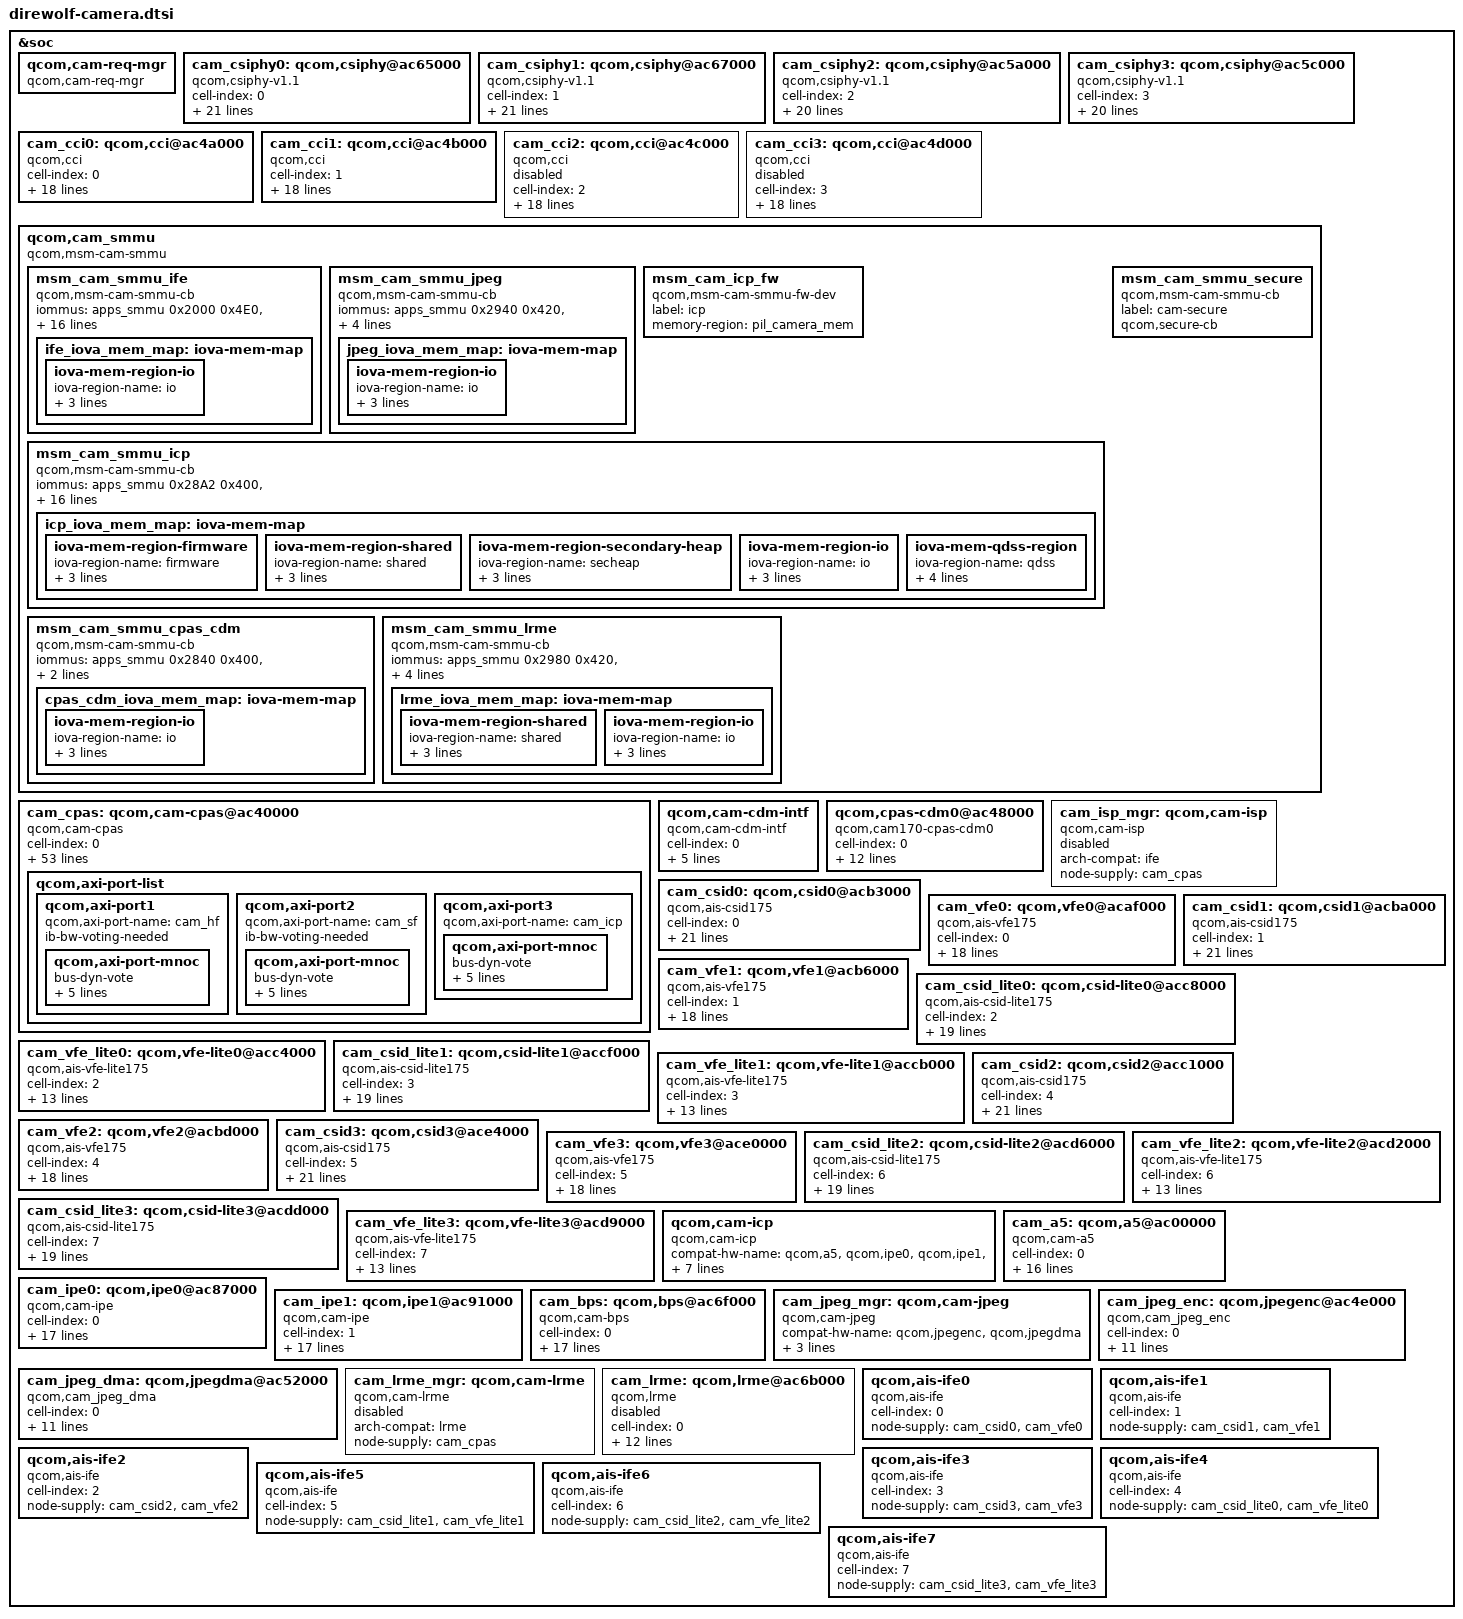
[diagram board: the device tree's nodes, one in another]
#include <dt-bindings/regulator/qcom,rpmh-regulator-levels.h>

&soc {
	qcom,cam-req-mgr {
		compatible = "qcom,cam-req-mgr";
		status = "ok";
	};

	cam_csiphy0: qcom,csiphy@ac65000 {
		cell-index = <0>;
		compatible = "qcom,csiphy-v1.1", "qcom,csiphy";
		reg = <0x0ac65000 0x2000>;
		reg-names = "csiphy";
		reg-cam-base = <0x65000>;
		interrupts = <GIC_SPI 477 IRQ_TYPE_EDGE_RISING>;
		interrupt-names = "csiphy";
		gdscr-supply = <&cam_cc_titan_top_gdsc>;
		csi-vdd-voltage = <1200000>;
		mipi-csi-vdd-supply = <&pm8540_a0_l11>;
		mipi-csi-vdd1p2-supply = <&pm8540_a0_l3>;
		regulator-names = "gdscr", "mipi-csi-vdd", "mipi-csi-vdd1p2";
		rgltr-cntrl-support;
		rgltr-min-voltage = <0 880000 1200000>;
		rgltr-max-voltage = <0 880000 1200000>;
		rgltr-load-current = <0 36000 21800>;
		clocks = <&camcc CAM_CC_CPHY_RX_CLK_SRC>,
			<&camcc CAM_CC_CSIPHY0_CLK>,
			<&camcc CAM_CC_CSI0PHYTIMER_CLK_SRC>,
			<&camcc CAM_CC_CSI0PHYTIMER_CLK>;
		clock-names = "cphy_rx_clk_src",
			"csiphy0_clk",
			"csi0phytimer_clk_src",
			"csi0phytimer_clk";
		src-clock-name = "csi0phytimer_clk_src";
		clock-cntl-level = "turbo";
		clock-rates =
			<400000000 0 300000000 0>;
		status = "ok";
		node-supply = <&cam_cpas>;
	};

	cam_csiphy1: qcom,csiphy@ac67000{
		cell-index = <1>;
		compatible = "qcom,csiphy-v1.1", "qcom,csiphy";
		reg = <0xac67000 0x2000>;
		reg-names = "csiphy";
		reg-cam-base = <0x67000>;
		interrupts = <GIC_SPI 478 IRQ_TYPE_EDGE_RISING>;
		interrupt-names = "csiphy";
		gdscr-supply = <&cam_cc_titan_top_gdsc>;
		csi-vdd-voltage = <1200000>;
		mipi-csi-vdd-supply = <&pm8540_a0_l11>;
		mipi-csi-vdd1p2-supply = <&pm8540_a0_l3>;
		regulator-names = "gdscr", "mipi-csi-vdd", "mipi-csi-vdd1p2";
		rgltr-cntrl-support;
		rgltr-min-voltage = <0 880000 1200000>;
		rgltr-max-voltage = <0 880000 1200000>;
		rgltr-load-current = <0 36000 21800>;
		clocks = <&camcc CAM_CC_CPHY_RX_CLK_SRC>,
			<&camcc CAM_CC_CSIPHY1_CLK>,
			<&camcc CAM_CC_CSI1PHYTIMER_CLK_SRC>,
			<&camcc CAM_CC_CSI1PHYTIMER_CLK>;
		clock-names = "cphy_rx_clk_src",
			"csiphy1_clk",
			"csi1phytimer_clk_src",
			"csi1phytimer_clk";
		src-clock-name = "csi1phytimer_clk_src";
		clock-cntl-level = "turbo";
		clock-rates =
			<400000000 0 300000000 0>;
		status = "ok";
		node-supply = <&cam_cpas>;
	};

	cam_csiphy2: qcom,csiphy@ac5a000 {
		cell-index = <2>;
		compatible = "qcom,csiphy-v1.1", "qcom,csiphy";
		reg = <0xac5a000 0x2000>;
		reg-names = "csiphy";
		reg-cam-base = <0x5a000>;
		interrupts = <GIC_SPI 479 IRQ_TYPE_EDGE_RISING>;
		interrupt-names = "csiphy";
		gdscr-supply = <&cam_cc_titan_top_gdsc>;
		csi-vdd-voltage = <1200000>;
		mipi-csi-vdd-supply = <&pm8540_g0_l8>;
		mipi-csi-vdd1p2-supply = <&pm8540_g0_l3>;
		regulator-names = "gdscr", "mipi-csi-vdd", "mipi-csi-vdd1p2";
		//rgltr-cntrl-support;
		rgltr-min-voltage = <0 880000 1200000>;
		rgltr-max-voltage = <0 880000 1200000>;
		rgltr-load-current = <0 36000 21800>;
		clocks = <&camcc CAM_CC_CPHY_RX_CLK_SRC>,
			<&camcc CAM_CC_CSIPHY2_CLK>,
			<&camcc CAM_CC_CSI2PHYTIMER_CLK_SRC>,
			<&camcc CAM_CC_CSI2PHYTIMER_CLK>;
		clock-names = "cphy_rx_clk_src",
			"csiphy2_clk",
			"csi2phytimer_clk_src",
			"csi2phytimer_clk";
		src-clock-name = "csi2phytimer_clk_src";
		clock-cntl-level = "turbo";
		clock-rates =
			<400000000 0 300000000 0>;
		status = "ok";
		node-supply = <&cam_cpas>;
	};

	cam_csiphy3: qcom,csiphy@ac5c000 {
		cell-index = <3>;
		compatible = "qcom,csiphy-v1.1", "qcom,csiphy";
		reg = <0xac5c000 0x2000>;
		reg-names = "csiphy";
		reg-cam-base = <0x5c000>;
		interrupts = <GIC_SPI 448 IRQ_TYPE_EDGE_RISING>;
		interrupt-names = "csiphy";
		gdscr-supply = <&cam_cc_titan_top_gdsc>;
		csi-vdd-voltage = <1200000>;
		mipi-csi-vdd-supply = <&pm8540_g0_l8>;
		mipi-csi-vdd1p2-supply = <&pm8540_g0_l3>;
		regulator-names = "gdscr", "mipi-csi-vdd", "mipi-csi-vdd1p2";
		//rgltr-cntrl-support;
		rgltr-min-voltage = <0 880000 1200000>;
		rgltr-max-voltage = <0 880000 1200000>;
		rgltr-load-current = <0 36000 21800>;
		clocks = <&camcc CAM_CC_CPHY_RX_CLK_SRC>,
			<&camcc CAM_CC_CSIPHY3_CLK>,
			<&camcc CAM_CC_CSI3PHYTIMER_CLK_SRC>,
			<&camcc CAM_CC_CSI3PHYTIMER_CLK>;
		clock-names = "cphy_rx_clk_src",
			"csiphy3_clk",
			"csi3phytimer_clk_src",
			"csi3phytimer_clk";
		src-clock-name = "csi3phytimer_clk_src";
		clock-cntl-level = "turbo";
		clock-rates =
			<400000000 0 300000000 0>;
		status = "ok";
		node-supply = <&cam_cpas>;
	};

	cam_cci0: qcom,cci@ac4a000 {
		cell-index = <0>;
		compatible = "qcom,cci";
		#address-cells = <1>;
		#size-cells = <0>;
		reg = <0xac4a000 0x1000>;
		reg-names = "cci";
		reg-cam-base = <0x4a000>;
		interrupt-names = "cci";
		interrupts = <GIC_SPI 460 IRQ_TYPE_EDGE_RISING>;
		status = "ok";
		gdscr-supply = <&cam_cc_titan_top_gdsc>;
		regulator-names = "gdscr";
		clocks = <&camcc CAM_CC_CCI_0_CLK_SRC>,
			<&camcc CAM_CC_CCI_0_CLK>;
		clock-names = "cci_0_clk_src",
			"cci_0_clk";
		src-clock-name = "cci_0_clk_src";
		clock-cntl-level = "lowsvs";
		clock-rates = <37500000 0>;
		pinctrl-names = "cam_default", "cam_suspend";
		pinctrl-0 = <&cci0_active &cci1_active>;
		pinctrl-1 = <&cci0_suspend &cci1_suspend>;
		node-supply = <&cam_cpas>;
		gpios = <&tlmm 113 0>,
			<&tlmm 114 0>,
			<&tlmm 115 0>,
			<&tlmm 116 0>;
		gpio-req-tbl-num = <0 1 2 3>;
		gpio-req-tbl-flags = <1 1 1 1>;
		gpio-req-tbl-label = "CCI_I2C_DATA0",
					"CCI_I2C_CLK0",
					"CCI_I2C_DATA1",
					"CCI_I2C_CLK1";

	};

	cam_cci1: qcom,cci@ac4b000 {
		cell-index = <1>;
		compatible = "qcom,cci";
		#address-cells = <1>;
		#size-cells = <0>;
		reg = <0xac4b000 0x1000>;
		reg-names = "cci";
		reg-cam-base = <0x4b000>;
		interrupt-names = "cci";
		interrupts = <GIC_SPI 271 IRQ_TYPE_EDGE_RISING>;
		status = "ok";
		gdscr-supply = <&cam_cc_titan_top_gdsc>;
		regulator-names = "gdscr";
		clocks = <&camcc CAM_CC_CCI_1_CLK_SRC>,
			<&camcc CAM_CC_CCI_1_CLK>;
		clock-names = "cci_1_clk_src",
			"cci_1_clk";
		src-clock-name = "cci_1_clk_src";
		clock-cntl-level = "lowsvs";
		clock-rates = <37500000 0>;
		pinctrl-names = "cam_default", "cam_suspend";
		pinctrl-0 = <&cci2_active &cci3_active>;
		pinctrl-1 = <&cci2_suspend &cci3_suspend>;
		node-supply = <&cam_cpas>;
		gpios = <&tlmm 10 0>,
			<&tlmm 11 0>,
			<&tlmm 123 0>,
			<&tlmm 124 0>;
		gpio-req-tbl-num = <0 1 2 3>;
		gpio-req-tbl-flags = <1 1 2 2>;
		gpio-req-tbl-label = "CCI_I2C_DATA2",
					"CCI_I2C_CLK2",
					"CCI_I2C_DATA3",
					"CCI_I2C_CLK3";

	};

	cam_cci2: qcom,cci@ac4c000 {
		cell-index = <2>;
		compatible = "qcom,cci";
		#address-cells = <1>;
		#size-cells = <0>;
		reg = <0xac4c000 0x1000>;
		reg-names = "cci";
		reg-cam-base = <0x4c000>;
		interrupt-names = "cci";
		interrupts = <GIC_SPI 651 IRQ_TYPE_EDGE_RISING>;
		status = "disabled";
		gdscr-supply = <&cam_cc_titan_top_gdsc>;
		regulator-names = "gdscr";
		clocks = <&camcc CAM_CC_CCI_2_CLK_SRC>,
			<&camcc CAM_CC_CCI_2_CLK>;
		clock-names = "cci_2_clk_src",
			"cci_2_clk";
		src-clock-name = "cci_2_clk_src";
		clock-cntl-level = "lowsvs";
		clock-rates = <37500000 0>;
		pinctrl-names = "cam_default", "cam_suspend";
		pinctrl-0 = <&cci4_active &cci5_active>;
		pinctrl-1 = <&cci4_suspend &cci5_suspend>;
		node-supply = <&cam_cpas>;
		gpios = <&tlmm 117 0>,
			<&tlmm 118 0>,
			<&tlmm 12 0>,
			<&tlmm 13 0>;
		gpio-req-tbl-num = <0 1 2 3>;
		gpio-req-tbl-flags = <1 1 1 1>;
		gpio-req-tbl-label = "CCI_I2C_DATA4",
					"CCI_I2C_CLK4",
					"CCI_I2C_DATA5",
					"CCI_I2C_CLK5";

	};

	cam_cci3: qcom,cci@ac4d000 {
		cell-index = <3>;
		compatible = "qcom,cci";
		#address-cells = <1>;
		#size-cells = <0>;
		reg = <0xac4d000 0x1000>;
		reg-names = "cci";
		reg-cam-base = <0x4d000>;
		interrupt-names = "cci";
		interrupts = <GIC_SPI 771 IRQ_TYPE_EDGE_RISING>;
		status = "disabled";
		gdscr-supply = <&cam_cc_titan_top_gdsc>;
		regulator-names = "gdscr";
		clocks = <&camcc CAM_CC_CCI_3_CLK_SRC>,
			<&camcc CAM_CC_CCI_3_CLK>;
		clock-names = "cci_3_clk_src",
			"cci_3_clk";
		src-clock-name = "cci_3_clk_src";
		clock-cntl-level = "lowsvs";
		clock-rates = <37500000 0>;
		pinctrl-names = "cam_default", "cam_suspend";
		pinctrl-0 = <&cci6_active &cci7_active>;
		pinctrl-1 = <&cci6_suspend &cci7_suspend>;
		node-supply = <&cam_cpas>;
		gpios = <&tlmm 145 0>,
			<&tlmm 146 0>,
			<&tlmm 164 0>,
			<&tlmm 165 0>;
		gpio-req-tbl-num = <0 1 2 3>;
		gpio-req-tbl-flags = <2 2 1 1>;
		gpio-req-tbl-label = "CCI_I2C_DATA6",
					"CCI_I2C_CLK6",
					"CCI_I2C_DATA7",
					"CCI_I2C_CLK7";

	};

	qcom,cam_smmu {
		compatible = "qcom,msm-cam-smmu";
		status = "ok";

		msm_cam_smmu_ife {
			compatible = "qcom,msm-cam-smmu-cb";
			iommus = <&apps_smmu 0x2000 0x4E0>,
				<&apps_smmu 0x2020 0x4E0>,
				<&apps_smmu 0x2040 0x4E0>,
				<&apps_smmu 0x2060 0x4E0>,
				<&apps_smmu 0x2080 0x4E0>,
				<&apps_smmu 0x20E0 0x4E0>,
				<&apps_smmu 0x20C0 0x4E0>,
				<&apps_smmu 0x20A0 0x4E0>,
				<&apps_smmu 0x2400 0x4E0>,
				<&apps_smmu 0x2420 0x4E0>,
				<&apps_smmu 0x2440 0x4E0>,
				<&apps_smmu 0x2460 0x4E0>,
				<&apps_smmu 0x2480 0x4E0>,
				<&apps_smmu 0x24E0 0x4E0>,
				<&apps_smmu 0x24C0 0x4E0>,
				<&apps_smmu 0x24A0 0x4E0>;
			label = "ife";
			ife_iova_mem_map: iova-mem-map {
				/* IO region is approximately 3.4 GB */
				iova-mem-region-io {
					iova-region-name = "io";
					iova-region-start = <0x7400000>;
					iova-region-len = <0xd8c00000>;
					iova-region-id = <0x3>;
					status = "ok";
				};
			};
		};
/*
		msm_cam_smmu_ife_cp {
			compatible = "qcom,msm-cam-smmu-cb";
			iommus = <&apps_smmu 0x2001 0x4E0>,
				<&apps_smmu 0x2021 0x4E0>,
				<&apps_smmu 0x2041 0x4E0>,
				<&apps_smmu 0x2061 0x4E0>,
				<&apps_smmu 0x2081 0x4E0>,
				<&apps_smmu 0x20E1 0x4E0>,
				<&apps_smmu 0x20C1 0x4E0>,
				<&apps_smmu 0x20A1 0x4E0>,
				<&apps_smmu 0x2401 0x4E0>,
				<&apps_smmu 0x2421 0x4E0>,
				<&apps_smmu 0x2441 0x4E0>,
				<&apps_smmu 0x2461 0x4E0>,
				<&apps_smmu 0x2481 0x4E0>,
				<&apps_smmu 0x24E1 0x4E0>,
				<&apps_smmu 0x24C1 0x4E0>,
				<&apps_smmu 0x24A1 0x4E0>;
			label = "ife-cp";
			qcom,secure-pixel-cb;
			qcom,iommu-vmid = <0xA>; // VMID_CP_PIXEL
			ife_cp_iova_mem_map: iova-mem-map {
				// IO region is approximately 2.5 GB
				iova-mem-region-io {
					iova-region-name = "io";
					iova-region-start = <0x7400000>;
					iova-region-len = <0x98C00000>;
					iova-region-id = <0x3>;
					status = "ok";
				};
			};
		};
*/
		msm_cam_smmu_jpeg {
			compatible = "qcom,msm-cam-smmu-cb";
			iommus = <&apps_smmu 0x2940 0x420>,
				<&apps_smmu 0x2960 0x420>,
				<&apps_smmu 0x2D40 0x420>,
				<&apps_smmu 0x2D60 0x420>;
			label = "jpeg";
			jpeg_iova_mem_map: iova-mem-map {
				/* IO region is approximately 3.4 GB */
				iova-mem-region-io {
					iova-region-name = "io";
					iova-region-start = <0x7400000>;
					iova-region-len = <0xd8c00000>;
					iova-region-id = <0x3>;
					status = "ok";
				};
			};
		};

		msm_cam_icp_fw {
			compatible = "qcom,msm-cam-smmu-fw-dev";
			label="icp";
			memory-region = <&pil_camera_mem>;
		};

		msm_cam_smmu_icp {
			compatible = "qcom,msm-cam-smmu-cb";
			iommus = <&apps_smmu 0x28A2 0x400>,
				<&apps_smmu 0x2800 0x420>,
				<&apps_smmu 0x2820 0x420>,
				<&apps_smmu 0x28C0 0x420>,
				<&apps_smmu 0x28E0 0x420>,
				<&apps_smmu 0x2900 0x420>,
				<&apps_smmu 0x2920 0x420>,
				<&apps_smmu 0x2CA2 0x400>,
				<&apps_smmu 0x2C00 0x420>,
				<&apps_smmu 0x2C20 0x420>,
				<&apps_smmu 0x2CC0 0x420>,
				<&apps_smmu 0x2CE0 0x420>,
				<&apps_smmu 0x2D00 0x420>,
				<&apps_smmu 0x2D20 0x420>;
			label = "icp";
			qcom,iommu-dma-addr-pool = <0x10c00000 0xcf300000>;
			icp_iova_mem_map: iova-mem-map {
				iova-mem-region-firmware {
					/* Firmware region is 5MB */
					iova-region-name = "firmware";
					iova-region-start = <0x0>;
					iova-region-len = <0x500000>;
					iova-region-id = <0x0>;
					status = "ok";
				};

				iova-mem-region-shared {
					/* Shared region is 150MB long */
					iova-region-name = "shared";
					iova-region-start = <0x7400000>;
					iova-region-len = <0x9600000>;
					iova-region-id = <0x1>;
					status = "ok";
				};

				iova-mem-region-secondary-heap {
					/* Secondary heap region is 1MB long */
					iova-region-name = "secheap";
					iova-region-start = <0x10A00000>;
					iova-region-len = <0x100000>;
					iova-region-id = <0x4>;
					status = "ok";
				};

				iova-mem-region-io {
					/* IO region is approximately 3.3 GB */
					iova-region-name = "io";
					iova-region-start = <0x10C00000>;
					iova-region-len = <0xCF300000>;
					iova-region-id = <0x3>;
					status = "ok";
				};

				iova-mem-qdss-region {
					/* QDSS region is appropriate 1MB */
					iova-region-name = "qdss";
					iova-region-start = <0x10B00000>;
					iova-region-len = <0x100000>;
					iova-region-id = <0x5>;
					qdss-phy-addr = <0x16790000>;
					status = "ok";
				};
			};
		};

		msm_cam_smmu_cpas_cdm {
			compatible = "qcom,msm-cam-smmu-cb";
			iommus = <&apps_smmu 0x2840 0x400>,
				<&apps_smmu 0x2C40 0x400>;
			label = "cpas-cdm0";
			cpas_cdm_iova_mem_map: iova-mem-map {
				iova-mem-region-io {
					/* IO region is approximately 3.4 GB */
					iova-region-name = "io";
					iova-region-start = <0x7400000>;
					iova-region-len = <0xd8c00000>;
					iova-region-id = <0x3>;
					status = "ok";
				};
			};
		};

		msm_cam_smmu_secure {
			compatible = "qcom,msm-cam-smmu-cb";
			label = "cam-secure";
			qcom,secure-cb;
		};

		msm_cam_smmu_lrme {
			compatible = "qcom,msm-cam-smmu-cb";
			iommus = <&apps_smmu 0x2980 0x420>,
				<&apps_smmu 0x29A0 0x420>,
				<&apps_smmu 0x2D80 0x420>,
				<&apps_smmu 0x2DA0 0x420>;
			label = "lrme";
			lrme_iova_mem_map: iova-mem-map {
				iova-mem-region-shared {
					/* Shared region is 100MB long */
					iova-region-name = "shared";
					iova-region-start = <0x7400000>;
					iova-region-len = <0x6400000>;
					iova-region-id = <0x1>;
					status = "ok";
				};
				/* IO region is approximately 3.3 GB */
				iova-mem-region-io {
					iova-region-name = "io";
					iova-region-start = <0xd800000>;
					iova-region-len = <0xd2800000>;
					iova-region-id = <0x3>;
					status = "ok";
				};
			};
		};
	};
	cam_cpas: qcom,cam-cpas@ac40000 {
		cell-index = <0>;
		compatible = "qcom,cam-cpas";
		label = "cpas";
		arch-compat = "cpas_top";
		status = "ok";
		reg-names = "cam_cpas_top", "cam_camnoc";
		reg = <0xac40000 0x1000>,
			<0xac22000 0xB400>;
		reg-cam-base = <0x40000 0x22000>;
		interrupt-names = "cpas_camnoc";
		interrupts = <GIC_SPI 459 IRQ_TYPE_EDGE_RISING>;

		camnoc-axi-min-ib-bw = <3000000000>;
		regulator-names = "camss-vdd";
		camss-vdd-supply = <&cam_cc_titan_top_gdsc>;

		clock-names =
			"gcc_axi_hf_clk",
			"gcc_axi_sf_clk",
			"slow_ahb_clk_src",
			"cpas_ahb_clk",
			"camnoc_axi_clk_src",
			"camnoc_axi_clk";

		clocks =
			<&gcc GCC_CAMERA_HF_AXI_CLK>,
			<&gcc GCC_CAMERA_SF_AXI_CLK>,
			<&camcc CAM_CC_SLOW_AHB_CLK_SRC>,
			<&camcc CAM_CC_CPAS_AHB_CLK>,
			<&camcc CAM_CC_CAMNOC_AXI_CLK_SRC>,
			<&camcc CAM_CC_CAMNOC_AXI_CLK>;

		src-clock-name = "camnoc_axi_clk_src";
		clock-rates =
			<0 0 0 0 0 0>,
			<0 0 19200000 0 19200000 0>,
			<0 0 80000000 0 150000000 0>,
			<0 0 80000000 0 266670000 0>,
			<0 0 80000000 0 320000000 0>,
			<0 0 80000000 0 400000000 0>,
			<0 0 80000000 0 480000000 0>;
		clock-cntl-level = "suspend", "minsvs", "lowsvs", "svs",
			"svs_l1", "nominal", "turbo";

		control-camnoc-axi-clk;
		camnoc-bus-width = <32>;
		camnoc-axi-clk-bw-margin-perc = <20>;

		interconnect-names = "cam_ahb";
		interconnects =<&gem_noc MASTER_APPSS_PROC
			&config_noc SLAVE_CAMERA_CFG>;
		bus-num-cases = <7>;
		bus-num-paths = <1>;
		bus-bw-KBps =
			<0 0>, <0 76800>, <0 76800>, <0 150000>, <0 150000>,
			<0 300000>, <0 300000>;
		vdd-corners = <RPMH_REGULATOR_LEVEL_RETENTION
			RPMH_REGULATOR_LEVEL_MIN_SVS
			RPMH_REGULATOR_LEVEL_LOW_SVS
			RPMH_REGULATOR_LEVEL_SVS
			RPMH_REGULATOR_LEVEL_SVS_L1
			RPMH_REGULATOR_LEVEL_NOM
			RPMH_REGULATOR_LEVEL_NOM_L1
			RPMH_REGULATOR_LEVEL_NOM_L2
			RPMH_REGULATOR_LEVEL_TURBO
			RPMH_REGULATOR_LEVEL_TURBO_L1>;
		vdd-corner-ahb-mapping = "suspend",
			"minsvs", "lowsvs", "svs", "svs_l1",
			"nominal", "nominal", "nominal",
			"turbo", "turbo";
		client-id-based;
		client-names =
			"csiphy0", "csiphy1", "csiphy2", "csiphy3",
			"cci0", "cci1", "cci2", "cci3",
			"csid0", "csid1", "csid2", "csid3",
			"csid4", "csid5", "csid6", "csid7",
			"ife0", "ife1", "ife2", "ife3",
			"ife4", "ife5", "ife6", "ife7",
			"ipe0", "ipe1", "cam-cdm-intf0", "cpas-cdm0",
			"bps0", "icp0", "jpeg-dma0", "jpeg-enc0",
			"lrmecpas0";
		client-axi-port-names =
			"cam_hf", "cam_hf", "cam_hf", "cam_hf",
			"cam_sf", "cam_sf", "cam_sf", "cam_sf",
			"cam_hf", "cam_hf", "cam_hf", "cam_hf",
			"cam_hf", "cam_hf", "cam_hf", "cam_hf",
			"cam_hf", "cam_hf", "cam_hf", "cam_hf",
			"cam_hf", "cam_hf", "cam_hf", "cam_hf",
			"cam_sf", "cam_sf", "cam_sf", "cam_sf",
			"cam_sf", "cam_icp", "cam_sf", "cam_sf",
			"cam_sf";
		//client-bus-camnoc-based;
		qcom,axi-port-list {
			qcom,axi-port1 {
				qcom,axi-port-name = "cam_hf";
				ib-bw-voting-needed;
				qcom,axi-port-mnoc {
					interconnect-names = "cam_hf_mnoc";
					bus-dyn-vote;
					bus-num-cases = <2>;
					bus-num-paths = <1>;
					interconnects = <&mmss_noc MASTER_CAMNOC_HF
						&mc_virt SLAVE_EBI1>;
					bus-bw-KBps =
						<0 0>, <0 0>;
				};
			};
			qcom,axi-port2 {
				qcom,axi-port-name = "cam_sf";
				ib-bw-voting-needed;
				qcom,axi-port-mnoc {
					interconnect-names = "cam_sf_mnoc";
					bus-dyn-vote;
					bus-num-cases = <2>;
					bus-num-paths = <1>;
					interconnects = <&mmss_noc MASTER_CAMNOC_SF
						&mc_virt SLAVE_EBI1>;
					bus-bw-KBps =
						<0 0>, <0 0>;
				};
			};
			qcom,axi-port3 {
				qcom,axi-port-name = "cam_icp";
				qcom,axi-port-mnoc {
					interconnect-names = "cam_icp_mnoc";
					bus-dyn-vote;
					bus-num-cases = <2>;
					bus-num-paths = <1>;
					interconnects = <&mmss_noc MASTER_CAMNOC_ICP
						&mc_virt SLAVE_EBI1>;
					bus-bw-KBps =
						<0 0>, <0 0>;
				};
			};
		};
	};

	qcom,cam-cdm-intf {
		compatible = "qcom,cam-cdm-intf";
		cell-index = <0>;
		node-supply = <&cam_cpas>;
		label = "cam-cdm-intf";
		num-hw-cdm = <1>;
		cdm-client-names = "vfe",
			"jpegdma",
			"jpegenc",
			"lrmecdm";
		status = "ok";
	};

	qcom,cpas-cdm0@ac48000 {
		cell-index = <0>;
		compatible = "qcom,cam170-cpas-cdm0";
		label = "cpas-cdm";
		reg = <0xac48000 0x1000>;
		reg-names = "cpas-cdm";
		reg-cam-base = <0x48000>;
		interrupts = <GIC_SPI 461 IRQ_TYPE_EDGE_RISING>;
		interrupt-names = "cpas-cdm";
		regulator-names = "camss";
		camss-supply = <&cam_cc_titan_top_gdsc>;
		node-supply = <&cam_cpas>;
		clock-names = "cam_cc_cpas_slow_ahb_clk",
			"cam_cc_cpas_ahb_clk";
		clocks = <&camcc CAM_CC_SLOW_AHB_CLK_SRC>,
			<&camcc CAM_CC_CPAS_AHB_CLK>;
		clock-rates = <0 0>;
		clock-cntl-level = "svs";
		cdm-client-names = "ife";
		status = "ok";
	};

	cam_isp_mgr: qcom,cam-isp {
		compatible = "qcom,cam-isp";
		arch-compat = "ife";
		status = "ok";
		node-supply = <&cam_cpas>;
	};

	cam_csid0: qcom,csid0@acb3000 {
		cell-index = <0>;
		compatible = "qcom,csid175";
		reg-names = "csid";
		reg = <0xacb3000 0x1000>;
		reg-cam-base = <0xb3000>;
		interrupt-names = "csid";
		interrupts = <GIC_SPI 464 IRQ_TYPE_EDGE_RISING>;
		regulator-names = "camss", "ife0";
		camss-supply = <&cam_cc_titan_top_gdsc>;
		ife0-supply = <&cam_cc_ife_0_gdsc>;
		clock-names =
			"ife_csid_clk_src",
			"ife_csid_clk",
			"cphy_rx_clk_src",
			"ife_cphy_rx_clk",
			"ife_clk_src",
			"ife_clk",
			"ife_axi_clk";
		clocks =
			<&camcc CAM_CC_IFE_0_CSID_CLK_SRC>,
			<&camcc CAM_CC_IFE_0_CSID_CLK>,
			<&camcc CAM_CC_CPHY_RX_CLK_SRC>,
			<&camcc CAM_CC_IFE_0_CPHY_RX_CLK>,
			<&camcc CAM_CC_IFE_0_CLK_SRC>,
			<&camcc CAM_CC_IFE_0_CLK>,
			<&camcc CAM_CC_IFE_0_AXI_CLK>;
		clock-rates =
			<400000000 0 0 0 400000000 0 0>,
			<400000000 0 0 0 558000000 0 0>,
			<480000000 0 0 0 637000000 0 0>,
			<600000000 0 0 0 760000000 0 0>;
		clock-cntl-level = "lowsvs", "svs", "svs_l1", "turbo";
		src-clock-name = "ife_csid_clk_src";
		clock-control-debugfs = "true";
		status = "ok";
		node-supply = <&cam_cpas>;
	};

	cam_vfe0: qcom,vfe0@acaf000 {
		cell-index = <0>;
		compatible = "qcom,vfe175";
		reg-names = "ife", "cam_camnoc";
		reg = <0xacaf000 0x4000>,
			<0xac22000 0xB400>;
		reg-cam-base = <0xaf000 0x22000>;
		interrupt-names = "ife";
		interrupts = <GIC_SPI 465 IRQ_TYPE_EDGE_RISING>;
		regulator-names = "camss", "ife0";
		camss-supply = <&cam_cc_titan_top_gdsc>;
		ife0-supply = <&cam_cc_ife_0_gdsc>;
		clock-names =
			"ife_clk_src",
			"ife_clk",
			"ife_axi_clk";
		clocks =
			<&camcc CAM_CC_IFE_0_CLK_SRC>,
			<&camcc CAM_CC_IFE_0_CLK>,
			<&camcc CAM_CC_IFE_0_AXI_CLK>;
		clock-rates =
			<400000000 0 0>,
			<558000000 0 0>,
			<637000000 0 0>,
			<760000000 0 0>;
		clock-cntl-level = "lowsvs", "svs", "svs_l1", "turbo";
		src-clock-name = "ife_clk_src";
		clock-control-debugfs = "true";
		clock-names-option =  "ife_dsp_clk";
		clocks-option = <&camcc CAM_CC_IFE_0_DSP_CLK>;
		clock-rates-option = <760000000>;
		status = "ok";
		node-supply = <&cam_cpas>;
	};

	cam_csid1: qcom,csid1@acba000 {
		cell-index = <1>;
		compatible = "qcom,csid175";
		reg-names = "csid";
		reg = <0xacba000 0x1000>;
		reg-cam-base = <0xba000>;
		interrupt-names = "csid";
		interrupts = <GIC_SPI 466 IRQ_TYPE_EDGE_RISING>;
		regulator-names = "camss", "ife1";
		camss-supply = <&cam_cc_titan_top_gdsc>;
		ife1-supply = <&cam_cc_ife_1_gdsc>;
		clock-names =
			"ife_csid_clk_src",
			"ife_csid_clk",
			"cphy_rx_clk_src",
			"ife_cphy_rx_clk",
			"ife_clk_src",
			"ife_clk",
			"ife_axi_clk";
		clocks =
			<&camcc CAM_CC_IFE_1_CSID_CLK_SRC>,
			<&camcc CAM_CC_IFE_1_CSID_CLK>,
			<&camcc CAM_CC_CPHY_RX_CLK_SRC>,
			<&camcc CAM_CC_IFE_1_CPHY_RX_CLK>,
			<&camcc CAM_CC_IFE_1_CLK_SRC>,
			<&camcc CAM_CC_IFE_1_CLK>,
			<&camcc CAM_CC_IFE_1_AXI_CLK>;
		clock-rates =
			<400000000 0 0 0 400000000 0 0>,
			<400000000 0 0 0 558000000 0 0>,
			<480000000 0 0 0 637000000 0 0>,
			<600000000 0 0 0 760000000 0 0>;
		clock-cntl-level = "lowsvs", "svs", "svs_l1", "turbo";
		src-clock-name = "ife_csid_clk_src";
		clock-control-debugfs = "true";
		status = "ok";
		node-supply = <&cam_cpas>;
	};

	cam_vfe1: qcom,vfe1@acb6000 {
		cell-index = <1>;
		compatible = "qcom,vfe175";
		reg-names = "ife", "cam_camnoc";
		reg = <0xacb6000 0x4000>,
			<0xac22000 0xB400>;
		reg-cam-base = <0xb6000 0x22000>;
		interrupt-names = "ife";
		interrupts = <GIC_SPI 467 IRQ_TYPE_EDGE_RISING>;
		regulator-names = "camss", "ife1";
		camss-supply = <&cam_cc_titan_top_gdsc>;
		ife1-supply = <&cam_cc_ife_1_gdsc>;
		clock-names =
			"ife_clk_src",
			"ife_clk",
			"ife_axi_clk";
		clocks =
			<&camcc CAM_CC_IFE_1_CLK_SRC>,
			<&camcc CAM_CC_IFE_1_CLK>,
			<&camcc CAM_CC_IFE_1_AXI_CLK>;
		clock-rates =
			<400000000 0 0>,
			<558000000 0 0>,
			<637000000 0 0>,
			<760000000 0 0>;
		clock-cntl-level = "lowsvs", "svs", "svs_l1", "turbo";
		src-clock-name = "ife_clk_src";
		clock-control-debugfs = "true";
		clock-names-option =  "ife_dsp_clk";
		clocks-option = <&camcc CAM_CC_IFE_1_DSP_CLK>;
		clock-rates-option = <760000000>;
		status = "ok";
		node-supply = <&cam_cpas>;
	};

	cam_csid_lite0: qcom,csid-lite0@acc8000 {
		cell-index = <2>;
		compatible = "qcom,csid-lite175";
		reg-names = "csid-lite";
		reg = <0xacc8000 0x1000>;
		reg-cam-base = <0xc8000>;
		interrupt-names = "csid-lite";
		interrupts = <GIC_SPI 468 IRQ_TYPE_EDGE_RISING>;
		regulator-names = "camss";
		camss-supply = <&cam_cc_titan_top_gdsc>;
		clock-names =
			"ife_csid_clk_src",
			"ife_csid_clk",
			"cphy_rx_clk_src",
			"ife_cphy_rx_clk",
			"ife_clk_src",
			"ife_clk";
		clocks =
			<&camcc CAM_CC_IFE_LITE_0_CSID_CLK_SRC>,
			<&camcc CAM_CC_IFE_LITE_0_CSID_CLK>,
			<&camcc CAM_CC_CPHY_RX_CLK_SRC>,
			<&camcc CAM_CC_IFE_LITE_0_CPHY_RX_CLK>,
			<&camcc CAM_CC_IFE_LITE_0_CLK_SRC>,
			<&camcc CAM_CC_IFE_LITE_0_CLK>;
		clock-rates =
			<400000000 0 0 0 320000000 0>,
			<400000000 0 0 0 400000000 0>,
			<480000000 0 0 0 480000000 0>,
			<600000000 0 0 0 600000000 0>;
		clock-cntl-level = "lowsvs", "svs", "svs_l1", "turbo";
		src-clock-name = "ife_csid_clk_src";
		clock-control-debugfs = "true";
		status = "ok";
		node-supply = <&cam_cpas>;
	};

	cam_vfe_lite0: qcom,vfe-lite0@acc4000 {
		cell-index = <2>;
		compatible = "qcom,vfe-lite175";
		reg-names = "ife-lite";
		reg = <0xacc4000 0x4000>;
		reg-cam-base = <0xc4000>;
		interrupt-names = "ife-lite";
		interrupts = <GIC_SPI 469 IRQ_TYPE_EDGE_RISING>;
		regulator-names = "camss";
		camss-supply = <&cam_cc_titan_top_gdsc>;
		clock-names =
			"ife_clk_src",
			"ife_clk";
		clocks =
			<&camcc CAM_CC_IFE_LITE_0_CLK_SRC>,
			<&camcc CAM_CC_IFE_LITE_0_CLK>;
		clock-rates =
			<320000000 0>,
			<400000000 0>,
			<480000000 0>,
			<600000000 0>;
		clock-cntl-level = "lowsvs", "svs", "svs_l1", "turbo";
		src-clock-name = "ife_clk_src";
		clock-control-debugfs = "true";
		status = "ok";
		node-supply = <&cam_cpas>;
	};

	cam_csid_lite1: qcom,csid-lite1@accf000 {
		cell-index = <3>;
		compatible = "qcom,csid-lite175";
		reg-names = "csid-lite";
		reg = <0xaccf000 0x1000>;
		reg-cam-base = <0xcf000>;
		interrupt-names = "csid-lite";
		interrupts = <GIC_SPI 359 IRQ_TYPE_EDGE_RISING>;
		regulator-names = "camss";
		camss-supply = <&cam_cc_titan_top_gdsc>;
		clock-names =
			"ife_csid_clk_src",
			"ife_csid_clk",
			"cphy_rx_clk_src",
			"ife_cphy_rx_clk",
			"ife_clk_src",
			"ife_clk";
		clocks =
			<&camcc CAM_CC_IFE_LITE_1_CSID_CLK_SRC>,
			<&camcc CAM_CC_IFE_LITE_1_CSID_CLK>,
			<&camcc CAM_CC_CPHY_RX_CLK_SRC>,
			<&camcc CAM_CC_IFE_LITE_1_CPHY_RX_CLK>,
			<&camcc CAM_CC_IFE_LITE_1_CLK_SRC>,
			<&camcc CAM_CC_IFE_LITE_1_CLK>;
		clock-rates =
			<400000000 0 0 0 320000000 0>,
			<400000000 0 0 0 400000000 0>,
			<480000000 0 0 0 480000000 0>,
			<600000000 0 0 0 600000000 0>;
		clock-cntl-level = "lowsvs", "svs", "svs_l1", "turbo";
		src-clock-name = "ife_csid_clk_src";
		clock-control-debugfs = "true";
		status = "ok";
		node-supply = <&cam_cpas>;
	};

	cam_vfe_lite1: qcom,vfe-lite1@accb000 {
		cell-index = <3>;
		compatible = "qcom,vfe-lite175";
		reg-names = "ife-lite";
		reg = <0xaccb000 0x4000>;
		reg-cam-base = <0xcb000>;
		interrupt-names = "ife-lite";
		interrupts = <GIC_SPI 360 IRQ_TYPE_EDGE_RISING>;
		regulator-names = "camss";
		camss-supply = <&cam_cc_titan_top_gdsc>;
		clock-names =
			"ife_clk_src",
			"ife_clk";
		clocks =
			<&camcc CAM_CC_IFE_LITE_1_CLK_SRC>,
			<&camcc CAM_CC_IFE_LITE_1_CLK>;
		clock-rates =
			<320000000 0>,
			<400000000 0>,
			<480000000 0>,
			<600000000 0>;
		clock-cntl-level = "lowsvs", "svs", "svs_l1", "turbo";
		src-clock-name = "ife_clk_src";
		clock-control-debugfs = "true";
		status = "ok";
		node-supply = <&cam_cpas>;
	};

	cam_csid2: qcom,csid2@acc1000 {
		cell-index = <4>;
		compatible = "qcom,csid175";
		reg-names = "csid";
		reg = <0xacc1000 0x1000>;
		reg-cam-base = <0xc1000>;
		interrupt-names = "csid";
		interrupts = <GIC_SPI 640 IRQ_TYPE_EDGE_RISING>;
		regulator-names = "camss", "ife2";
		camss-supply = <&cam_cc_titan_top_gdsc>;
		ife2-supply = <&cam_cc_ife_2_gdsc>;
		clock-names =
			"ife_csid_clk_src",
			"ife_csid_clk",
			"cphy_rx_clk_src",
			"ife_cphy_rx_clk",
			"ife_clk_src",
			"ife_clk",
			"ife_axi_clk";
		clocks =
			<&camcc CAM_CC_IFE_2_CSID_CLK_SRC>,
			<&camcc CAM_CC_IFE_2_CSID_CLK>,
			<&camcc CAM_CC_CPHY_RX_CLK_SRC>,
			<&camcc CAM_CC_IFE_2_CPHY_RX_CLK>,
			<&camcc CAM_CC_IFE_2_CLK_SRC>,
			<&camcc CAM_CC_IFE_2_CLK>,
			<&camcc CAM_CC_IFE_2_AXI_CLK>;
		clock-rates =
			<400000000 0 0 0 400000000 0 0>,
			<400000000 0 0 0 558000000 0 0>,
			<480000000 0 0 0 637000000 0 0>,
			<600000000 0 0 0 760000000 0 0>;
		clock-cntl-level = "lowsvs", "svs", "svs_l1", "turbo";
		src-clock-name = "ife_csid_clk_src";
		clock-control-debugfs = "true";
		status = "ok";
		node-supply = <&cam_cpas>;
	};

	cam_vfe2: qcom,vfe2@acbd000 {
		cell-index = <4>;
		compatible = "qcom,vfe175";
		reg-names = "ife", "cam_camnoc";
		reg = <0xacbd000 0x4000>,
			<0xac22000 0xB400>;
		reg-cam-base = <0xbd000 0x22000>;
		interrupt-names = "ife";
		interrupts = <GIC_SPI 641 IRQ_TYPE_EDGE_RISING>;
		regulator-names = "camss", "ife2";
		camss-supply = <&cam_cc_titan_top_gdsc>;
		ife2-supply = <&cam_cc_ife_2_gdsc>;
		clock-names =
			"ife_clk_src",
			"ife_clk",
			"ife_axi_clk";
		clocks =
			<&camcc CAM_CC_IFE_2_CLK_SRC>,
			<&camcc CAM_CC_IFE_2_CLK>,
			<&camcc CAM_CC_IFE_2_AXI_CLK>;
		clock-rates =
			<400000000 0 0>,
			<558000000 0 0>,
			<637000000 0 0>,
			<760000000 0 0>;
		clock-cntl-level = "lowsvs", "svs", "svs_l1", "turbo";
		src-clock-name = "ife_clk_src";
		clock-control-debugfs = "true";
		clock-names-option =  "ife_dsp_clk";
		clocks-option = <&camcc CAM_CC_IFE_2_DSP_CLK>;
		clock-rates-option = <760000000>;
		status = "ok";
		node-supply = <&cam_cpas>;
	};

	cam_csid3: qcom,csid3@ace4000 {
		cell-index = <5>;
		compatible = "qcom,csid175";
		reg-names = "csid";
		reg = <0xace4000 0x1000>;
		reg-cam-base = <0xe4000>;
		interrupt-names = "csid";
		interrupts = <GIC_SPI 762 IRQ_TYPE_EDGE_RISING>;
		regulator-names = "camss", "ife3";
		camss-supply = <&cam_cc_titan_top_gdsc>;
		ife3-supply = <&cam_cc_ife_3_gdsc>;
		clock-names =
			"ife_csid_clk_src",
			"ife_csid_clk",
			"cphy_rx_clk_src",
			"ife_cphy_rx_clk",
			"ife_clk_src",
			"ife_clk",
			"ife_axi_clk";
		clocks =
			<&camcc CAM_CC_IFE_3_CSID_CLK_SRC>,
			<&camcc CAM_CC_IFE_3_CSID_CLK>,
			<&camcc CAM_CC_CPHY_RX_CLK_SRC>,
			<&camcc CAM_CC_IFE_3_CPHY_RX_CLK>,
			<&camcc CAM_CC_IFE_3_CLK_SRC>,
			<&camcc CAM_CC_IFE_3_CLK>,
			<&camcc CAM_CC_IFE_3_AXI_CLK>;
		clock-rates =
			<400000000 0 0 0 400000000 0 0>,
			<400000000 0 0 0 558000000 0 0>,
			<480000000 0 0 0 637000000 0 0>,
			<600000000 0 0 0 760000000 0 0>;
		clock-cntl-level = "lowsvs", "svs", "svs_l1", "turbo";
		src-clock-name = "ife_csid_clk_src";
		clock-control-debugfs = "true";
		status = "ok";
		node-supply = <&cam_cpas>;
	};

	cam_vfe3: qcom,vfe3@ace0000 {
		cell-index = <5>;
		compatible = "qcom,vfe175";
		reg-names = "ife", "cam_camnoc";
		reg = <0xace0000 0x4000>,
			<0xac22000 0xB400>;
		reg-cam-base = <0xe0000 0x22000>;
		interrupt-names = "ife";
		interrupts = <GIC_SPI 764 IRQ_TYPE_EDGE_RISING>;
		regulator-names = "camss", "ife3";
		camss-supply = <&cam_cc_titan_top_gdsc>;
		ife3-supply = <&cam_cc_ife_3_gdsc>;
		clock-names =
			"ife_clk_src",
			"ife_clk",
			"ife_axi_clk";
		clocks =
			<&camcc CAM_CC_IFE_3_CLK_SRC>,
			<&camcc CAM_CC_IFE_3_CLK>,
			<&camcc CAM_CC_IFE_3_AXI_CLK>;
		clock-rates =
			<400000000 0 0>,
			<558000000 0 0>,
			<637000000 0 0>,
			<760000000 0 0>;
		clock-cntl-level = "lowsvs", "svs", "svs_l1", "turbo";
		src-clock-name = "ife_clk_src";
		clock-control-debugfs = "true";
		clock-names-option =  "ife_dsp_clk";
		clocks-option = <&camcc CAM_CC_IFE_3_DSP_CLK>;
		clock-rates-option = <760000000>;
		status = "ok";
		node-supply = <&cam_cpas>;
	};

	cam_csid_lite2: qcom,csid-lite2@acd6000 {
		cell-index = <6>;
		compatible = "qcom,csid-lite175";
		reg-names = "csid-lite";
		reg = <0xacd6000 0x1000>;
		reg-cam-base = <0xd6000>;
		interrupt-names = "csid-lite";
		interrupts = <GIC_SPI 759 IRQ_TYPE_EDGE_RISING>;
		regulator-names = "camss";
		camss-supply = <&cam_cc_titan_top_gdsc>;
		clock-names =
			"ife_csid_clk_src",
			"ife_csid_clk",
			"cphy_rx_clk_src",
			"ife_cphy_rx_clk",
			"ife_clk_src",
			"ife_clk";
		clocks =
			<&camcc CAM_CC_IFE_LITE_2_CSID_CLK_SRC>,
			<&camcc CAM_CC_IFE_LITE_2_CSID_CLK>,
			<&camcc CAM_CC_CPHY_RX_CLK_SRC>,
			<&camcc CAM_CC_IFE_LITE_2_CPHY_RX_CLK>,
			<&camcc CAM_CC_IFE_LITE_2_CLK_SRC>,
			<&camcc CAM_CC_IFE_LITE_2_CLK>;
		clock-rates =
			<400000000 0 0 0 320000000 0>,
			<400000000 0 0 0 400000000 0>,
			<480000000 0 0 0 480000000 0>,
			<600000000 0 0 0 600000000 0>;
		clock-cntl-level = "lowsvs", "svs", "svs_l1", "turbo";
		src-clock-name = "ife_csid_clk_src";
		clock-control-debugfs = "true";
		status = "ok";
		node-supply = <&cam_cpas>;
	};

	cam_vfe_lite2: qcom,vfe-lite2@acd2000 {
		cell-index = <6>;
		compatible = "qcom,vfe-lite175";
		reg-names = "ife-lite";
		reg = <0xacd2000 0x4000>;
		reg-cam-base = <0xd2000>;
		interrupt-names = "ife-lite";
		interrupts = <GIC_SPI 761 IRQ_TYPE_EDGE_RISING>;
		regulator-names = "camss";
		camss-supply = <&cam_cc_titan_top_gdsc>;
		clock-names =
			"ife_clk_src",
			"ife_clk";
		clocks =
			<&camcc CAM_CC_IFE_LITE_2_CLK_SRC>,
			<&camcc CAM_CC_IFE_LITE_2_CLK>;
		clock-rates =
			<320000000 0>,
			<400000000 0>,
			<480000000 0>,
			<600000000 0>;
		clock-cntl-level = "lowsvs", "svs", "svs_l1", "turbo";
		src-clock-name = "ife_clk_src";
		clock-control-debugfs = "true";
		status = "ok";
		node-supply = <&cam_cpas>;
	};

	cam_csid_lite3: qcom,csid-lite3@acdd000 {
		cell-index = <7>;
		compatible = "qcom,csid-lite175";
		reg-names = "csid-lite";
		reg = <0xacdd000 0x1000>;
		reg-cam-base = <0xdd000>;
		interrupt-names = "csid-lite";
		interrupts = <GIC_SPI 758 IRQ_TYPE_EDGE_RISING>;
		regulator-names = "camss";
		camss-supply = <&cam_cc_titan_top_gdsc>;
		clock-names =
			"ife_csid_clk_src",
			"ife_csid_clk",
			"cphy_rx_clk_src",
			"ife_cphy_rx_clk",
			"ife_clk_src",
			"ife_clk";
		clocks =
			<&camcc CAM_CC_IFE_LITE_3_CSID_CLK_SRC>,
			<&camcc CAM_CC_IFE_LITE_3_CSID_CLK>,
			<&camcc CAM_CC_CPHY_RX_CLK_SRC>,
			<&camcc CAM_CC_IFE_LITE_3_CPHY_RX_CLK>,
			<&camcc CAM_CC_IFE_LITE_3_CLK_SRC>,
			<&camcc CAM_CC_IFE_LITE_3_CLK>;
		clock-rates =
			<400000000 0 0 0 320000000 0>,
			<400000000 0 0 0 400000000 0>,
			<480000000 0 0 0 480000000 0>,
			<600000000 0 0 0 600000000 0>;
		clock-cntl-level = "lowsvs", "svs", "svs_l1", "turbo";
		src-clock-name = "ife_csid_clk_src";
		clock-control-debugfs = "true";
		status = "ok";
		node-supply = <&cam_cpas>;
	};

	cam_vfe_lite3: qcom,vfe-lite3@acd9000 {
		cell-index = <7>;
		compatible = "qcom,vfe-lite175";
		reg-names = "ife-lite";
		reg = <0xacd9000 0x4000>;
		reg-cam-base = <0xd9000>;
		interrupt-names = "ife-lite";
		interrupts = <GIC_SPI 760 IRQ_TYPE_EDGE_RISING>;
		regulator-names = "camss";
		camss-supply = <&cam_cc_titan_top_gdsc>;
		clock-names =
			"ife_clk_src",
			"ife_clk";
		clocks =
			<&camcc CAM_CC_IFE_LITE_3_CLK_SRC>,
			<&camcc CAM_CC_IFE_LITE_3_CLK>;
		clock-rates =
			<320000000 0>,
			<400000000 0>,
			<480000000 0>,
			<600000000 0>;
		clock-cntl-level = "lowsvs", "svs", "svs_l1", "turbo";
		src-clock-name = "ife_clk_src";
		clock-control-debugfs = "true";
		status = "ok";
		node-supply = <&cam_cpas>;
	};

	qcom,cam-icp {
		compatible = "qcom,cam-icp";
		compat-hw-name = "qcom,a5",
			"qcom,ipe0",
			"qcom,ipe1",
			"qcom,bps";
		num-a5 = <1>;
		num-ipe = <2>;
		num-bps = <1>;
		icp_pc_en;
		ipe_bps_pc_en;
		status = "ok";
		node-supply = <&cam_cpas>;
	};

	cam_a5: qcom,a5@ac00000 {
		cell-index = <0>;
		compatible = "qcom,cam-a5";
		reg = <0xac00000 0x6000>,
			<0xac10000 0x8000>,
			<0xac18000 0x3000>;
		reg-names = "a5_qgic", "a5_sierra", "a5_csr";
		reg-cam-base = <0x00000 0x10000 0x18000>;
		interrupts = <GIC_SPI 463 IRQ_TYPE_EDGE_RISING>;
		interrupt-names = "a5";
		regulator-names = "camss-vdd";
		camss-vdd-supply = <&cam_cc_titan_top_gdsc>;
		clock-names =
			"soc_fast_ahb",
			"icp_ahb_clk",
			"icp_clk_src",
			"icp_clk";
		clocks =
			<&camcc CAM_CC_FAST_AHB_CLK_SRC>,
			<&camcc CAM_CC_ICP_AHB_CLK>,
			<&camcc CAM_CC_ICP_CLK_SRC>,
			<&camcc CAM_CC_ICP_CLK>;

		clock-rates =
			<200000000 0 400000000 0>,
			<400000000 0 600000000 0>;
		clock-cntl-level = "svs", "turbo";
		fw_name = "CAMERA_ICP.elf";
		ubwc-cfg = <0x7B 0x1EF>;
		status = "ok";
		node-supply = <&cam_cpas>;
	};

	cam_ipe0: qcom,ipe0@ac87000 {
		cell-index = <0>;
		compatible = "qcom,cam-ipe";
		reg = <0xac87000 0x3000>;
		reg-names = "ipe0_top";
		reg-cam-base = <0x87000>;
		regulator-names = "ipe0-vdd";
		ipe0-vdd-supply = <&cam_cc_ipe_0_gdsc>;
		clock-names =
			"ipe_0_ahb_clk",
			"ipe_0_areg_clk",
			"ipe_0_axi_clk",
			"ipe_0_clk_src",
			"ipe_0_clk";
		src-clock-name = "ipe_0_clk_src";
		clock-control-debugfs = "true";
		clocks =
			<&camcc CAM_CC_IPE_0_AHB_CLK>,
			<&camcc CAM_CC_IPE_0_AREG_CLK>,
			<&camcc CAM_CC_IPE_0_AXI_CLK>,
			<&camcc CAM_CC_IPE_0_CLK_SRC>,
			<&camcc CAM_CC_IPE_0_CLK>;

		clock-rates =
			<0 0 0 300000000 0>,
			<0 0 0 475000000 0>,
			<0 0 0 520000000 0>,
			<0 0 0 600000000 0>,
			<0 0 0 600000000 0>;
		clock-cntl-level = "lowsvs", "svs", "svs_l1",
				"nominal", "turbo";
		status = "ok";
		node-supply = <&cam_cpas>;
	};

	cam_ipe1: qcom,ipe1@ac91000 {
		cell-index = <1>;
		compatible = "qcom,cam-ipe";
		reg = <0xac91000 0x3000>;
		reg-names = "ipe1_top";
		reg-cam-base = <0x91000>;
		regulator-names = "ipe1-vdd";
		ipe1-vdd-supply = <&cam_cc_ipe_1_gdsc>;
		clock-names =
			"ipe_1_ahb_clk",
			"ipe_1_areg_clk",
			"ipe_1_axi_clk",
			"ipe_1_clk_src",
			"ipe_1_clk";
		src-clock-name = "ipe_1_clk_src";
		clock-control-debugfs = "true";
		clocks =
			<&camcc CAM_CC_IPE_1_AHB_CLK>,
			<&camcc CAM_CC_IPE_1_AREG_CLK>,
			<&camcc CAM_CC_IPE_1_AXI_CLK>,
			<&camcc CAM_CC_IPE_0_CLK_SRC>,
			<&camcc CAM_CC_IPE_1_CLK>;

		clock-rates =
			<0 0 0 300000000 0>,
			<0 0 0 475000000 0>,
			<0 0 0 520000000 0>,
			<0 0 0 600000000 0>,
			<0 0 0 600000000 0>;
		clock-cntl-level = "lowsvs", "svs", "svs_l1",
				"nominal", "turbo";
		status = "ok";
		node-supply = <&cam_cpas>;
	};

	cam_bps: qcom,bps@ac6f000 {
		cell-index = <0>;
		compatible = "qcom,cam-bps";
		reg = <0xac6f000 0x3000>;
		reg-names = "bps_top";
		reg-cam-base = <0x6f000>;
		regulator-names = "bps-vdd";
		bps-vdd-supply = <&cam_cc_bps_gdsc>;
		clock-names =
			"bps_ahb_clk",
			"bps_areg_clk",
			"bps_axi_clk",
			"bps_clk_src",
			"bps_clk";
		src-clock-name = "bps_clk_src";
		clock-control-debugfs = "true";
		clocks =
			<&camcc CAM_CC_BPS_AHB_CLK>,
			<&camcc CAM_CC_BPS_AREG_CLK>,
			<&camcc CAM_CC_BPS_AXI_CLK>,
			<&camcc CAM_CC_BPS_CLK_SRC>,
			<&camcc CAM_CC_BPS_CLK>;

		clock-rates =
			<0 0 0 200000000 0>,
			<0 0 0 400000000 0>,
			<0 0 0 480000000 0>,
			<0 0 0 600000000 0>,
			<0 0 0 600000000 0>;
		clock-cntl-level = "lowsvs", "svs", "svs_l1",
				"nominal", "turbo";
		status = "ok";
		node-supply = <&cam_cpas>;
	};

	cam_jpeg_mgr: qcom,cam-jpeg {
		compatible = "qcom,cam-jpeg";
		compat-hw-name = "qcom,jpegenc",
			"qcom,jpegdma";
		num-jpeg-enc = <1>;
		num-jpeg-dma = <1>;
		status = "ok";
		node-supply = <&cam_cpas>;
	};

	cam_jpeg_enc: qcom,jpegenc@ac4e000 {
		cell-index = <0>;
		compatible = "qcom,cam_jpeg_enc";
		reg-names = "jpege_hw";
		reg = <0xac4e000 0x4000>;
		reg-cam-base = <0x4e000>;
		interrupt-names = "jpeg";
		interrupts = <GIC_SPI 474 IRQ_TYPE_EDGE_RISING>;
		regulator-names = "camss-vdd";
		camss-vdd-supply = <&cam_cc_titan_top_gdsc>;
		clock-names =
			"jpegenc_clk_src",
			"jpegenc_clk";
		clocks =
			<&camcc CAM_CC_JPEG_CLK_SRC>,
			<&camcc CAM_CC_JPEG_CLK>;

		clock-rates = <600000000 0>;
		src-clock-name = "jpegenc_clk_src";
		clock-cntl-level = "nominal";
		status = "ok";
		node-supply = <&cam_cpas>;
	};

	cam_jpeg_dma: qcom,jpegdma@ac52000{
		cell-index = <0>;
		compatible = "qcom,cam_jpeg_dma";
		reg-names = "jpegdma_hw";
		reg = <0xac52000 0x4000>;
		reg-cam-base = <0x52000>;
		interrupt-names = "jpegdma";
		interrupts = <GIC_SPI 475 IRQ_TYPE_EDGE_RISING>;
		regulator-names = "camss-vdd";
		camss-vdd-supply = <&cam_cc_titan_top_gdsc>;
		clock-names =
			"jpegdma_clk_src",
			"jpegdma_clk";
		clocks =
			<&camcc CAM_CC_JPEG_CLK_SRC>,
			<&camcc CAM_CC_JPEG_CLK>;

		clock-rates = <600000000 0>;
		src-clock-name = "jpegdma_clk_src";
		clock-cntl-level = "nominal";
		status = "ok";
		node-supply = <&cam_cpas>;
	};


	cam_lrme_mgr: qcom,cam-lrme {
		compatible = "qcom,cam-lrme";
		arch-compat = "lrme";
		status = "ok";
		node-supply = <&cam_cpas>;
	};

	cam_lrme: qcom,lrme@ac6b000 {
		cell-index = <0>;
		compatible = "qcom,lrme";
		reg-names = "lrme";
		reg = <0xac6b000 0xa00>;
		reg-cam-base = <0x6b000>;
		interrupt-names = "lrme";
		interrupts = <0 476 0>;
		regulator-names = "camss";
		camss-supply = <&cam_cc_titan_top_gdsc>;
		clock-names =
			"lrme_clk_src",
			"lrme_clk";
		clocks =
			<&camcc CAM_CC_LRME_CLK_SRC>,
			<&camcc CAM_CC_LRME_CLK>;
		clock-rates =
			<240000000 0>,
			<300000000 0>,
			<320000000 0>,
			<400000000 0>;
		clock-cntl-level = "lowsvs", "svs", "svs_l1", "turbo";
		src-clock-name = "lrme_clk_src";
		status = "ok";
		node-supply = <&cam_cpas>;
	};
};

/*Overlay to use AIS and disable unused devices*/
&cam_isp_mgr {
	status = "disabled";
};

&cam_csid0 {
	compatible = "qcom,ais-csid175";
};

&cam_vfe0 {
	compatible = "qcom,ais-vfe175";
};

&cam_csid1 {
	compatible = "qcom,ais-csid175";
};

&cam_vfe1 {
	compatible = "qcom,ais-vfe175";
};

&cam_csid2 {
	compatible = "qcom,ais-csid175";
};

&cam_vfe2 {
	compatible = "qcom,ais-vfe175";
};

&cam_csid3 {
	compatible = "qcom,ais-csid175";
};

&cam_vfe3 {
	compatible = "qcom,ais-vfe175";
};

&cam_csid_lite0 {
	compatible = "qcom,ais-csid-lite175";
};

&cam_vfe_lite0 {
	compatible = "qcom,ais-vfe-lite175";
};

&cam_csid_lite1 {
	compatible = "qcom,ais-csid-lite175";
};

&cam_vfe_lite1 {
	compatible = "qcom,ais-vfe-lite175";
};

&cam_csid_lite2 {
	compatible = "qcom,ais-csid-lite175";
};

&cam_vfe_lite2 {
	compatible = "qcom,ais-vfe-lite175";
};

&cam_csid_lite3 {
	compatible = "qcom,ais-csid-lite175";
};

&cam_vfe_lite3 {
	compatible = "qcom,ais-vfe-lite175";
};

&cam_lrme_mgr {
	status = "disabled";
};
&cam_lrme {
	status = "disabled";
};

&soc {
	/delete-node/ cam_isp_mgr;
	/delete-node/ cam_lrme_mgr;
	/delete-node/ cam_lrme;

	qcom,ais-ife0 {
		compatible = "qcom,ais-ife";
		cell-index = <0>;
		status = "ok";
		node-supply=<&cam_csid0 &cam_vfe0>;
	};

	qcom,ais-ife1 {
		compatible = "qcom,ais-ife";
		cell-index = <1>;
		status = "ok";
		node-supply=<&cam_csid1 &cam_vfe1>;
	};

	qcom,ais-ife2 {
		compatible = "qcom,ais-ife";
		cell-index = <2>;
		status = "ok";
		node-supply=<&cam_csid2 &cam_vfe2>;
	};

	qcom,ais-ife3 {
		compatible = "qcom,ais-ife";
		cell-index = <3>;
		status = "ok";
		node-supply=<&cam_csid3 &cam_vfe3>;
	};

	qcom,ais-ife4 {
		compatible = "qcom,ais-ife";
		cell-index = <4>;
		status = "ok";
		node-supply=<&cam_csid_lite0 &cam_vfe_lite0>;
	};

	qcom,ais-ife5 {
		compatible = "qcom,ais-ife";
		cell-index = <5>;
		status = "ok";
		node-supply=<&cam_csid_lite1 &cam_vfe_lite1>;
	};

	qcom,ais-ife6 {
		compatible = "qcom,ais-ife";
		cell-index = <6>;
		status = "ok";
		node-supply=<&cam_csid_lite2 &cam_vfe_lite2>;
	};

	qcom,ais-ife7 {
		compatible = "qcom,ais-ife";
		cell-index = <7>;
		status = "ok";
		node-supply=<&cam_csid_lite3 &cam_vfe_lite3>;
	};
};
